AUTOSAR XML (schema 4-2-2)
package /Components
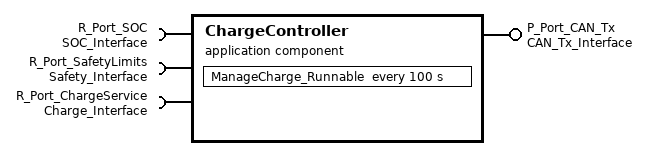
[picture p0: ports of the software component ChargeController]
  application sw component type ChargeController
    provide port P_Port_CAN_Tx: provided-interface=CAN_Tx_Interface
    require port R_Port_SOC: required-interface=SOC_Interface
    require port R_Port_SafetyLimits: required-interface=Safety_Interface
    require port R_Port_ChargeService: required-interface=Charge_Interface
    behavior ChargeController_Behavior
      external trigger occurred event Charger_Request: start-on-event=ManageCharge_Runnable
      timing event Charge_Control_100ms: start-on-event=ManageCharge_Runnable, period=100
      runnable ManageCharge_Runnable: minimum-start-interval=100, symbol=ChargeController_ManageCharge
        data-receive-point-by-arguments:
          access Read_SOC: accessed-variable=R_Port_SOC.SOC
          access Read_Confidence: accessed-variable=R_Port_SOC.confidence
          access Read_SafetyLimits: accessed-variable=R_Port_SafetyLimits.safetyLimits
        sync call ChargeSession_Call: operation=R_Port_ChargeService.ChargeRequest, timeout=200
